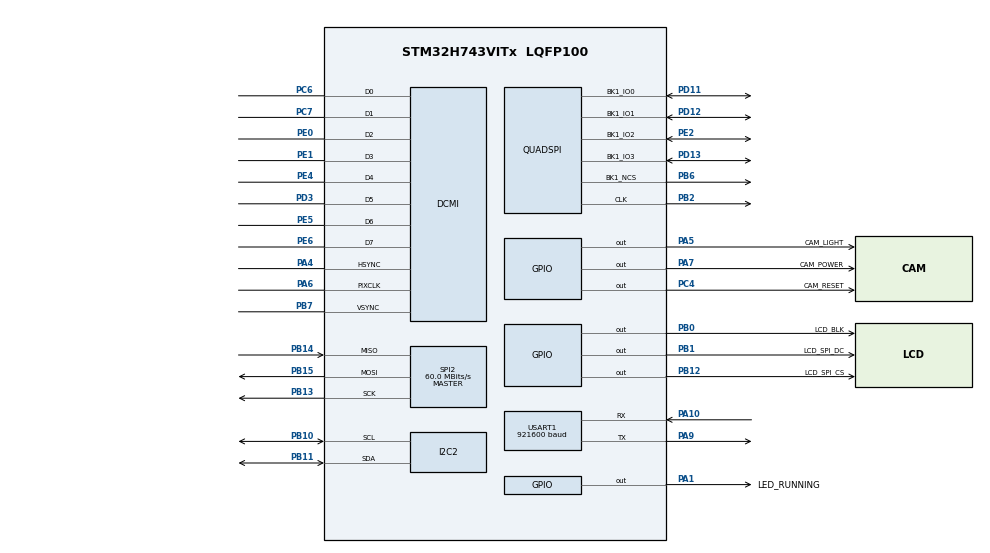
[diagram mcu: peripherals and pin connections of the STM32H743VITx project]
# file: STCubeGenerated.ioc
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CORTEX_M7.AccessPermission-Cortex_Memory_Protection_Unit_Region0_Settings=MPU_REGION_FULL_ACCESS
CORTEX_M7.AccessPermission-Cortex_Memory_Protection_Unit_Region1_Settings=MPU_REGION_FULL_ACCESS
CORTEX_M7.AccessPermission-Cortex_Memory_Protection_Unit_Region2_Settings=MPU_REGION_FULL_ACCESS
CORTEX_M7.AccessPermission-Cortex_Memory_Protection_Unit_Region3_Settings=MPU_REGION_FULL_ACCESS
CORTEX_M7.BaseAddress-Cortex_Memory_Protection_Unit_Region0_Settings=0x24000000
CORTEX_M7.BaseAddress-Cortex_Memory_Protection_Unit_Region1_Settings=0x30000000
CORTEX_M7.BaseAddress-Cortex_Memory_Protection_Unit_Region2_Settings=0x30040000
CORTEX_M7.BaseAddress-Cortex_Memory_Protection_Unit_Region3_Settings=0x38000000
CORTEX_M7.CPU_DCache=Enabled
CORTEX_M7.CPU_ICache=Enabled
CORTEX_M7.Enable-Cortex_Memory_Protection_Unit_Region0_Settings=MPU_REGION_ENABLE
CORTEX_M7.Enable-Cortex_Memory_Protection_Unit_Region1_Settings=MPU_REGION_ENABLE
CORTEX_M7.Enable-Cortex_Memory_Protection_Unit_Region2_Settings=MPU_REGION_ENABLE
CORTEX_M7.Enable-Cortex_Memory_Protection_Unit_Region3_Settings=MPU_REGION_ENABLE
CORTEX_M7.IsBufferable-Cortex_Memory_Protection_Unit_Region0_Settings=MPU_ACCESS_BUFFERABLE
CORTEX_M7.IsBufferable-Cortex_Memory_Protection_Unit_Region1_Settings=MPU_ACCESS_BUFFERABLE
CORTEX_M7.IsBufferable-Cortex_Memory_Protection_Unit_Region2_Settings=MPU_ACCESS_BUFFERABLE
CORTEX_M7.IsBufferable-Cortex_Memory_Protection_Unit_Region3_Settings=MPU_ACCESS_BUFFERABLE
CORTEX_M7.IsCacheable-Cortex_Memory_Protection_Unit_Region0_Settings=MPU_ACCESS_CACHEABLE
CORTEX_M7.IsCacheable-Cortex_Memory_Protection_Unit_Region1_Settings=MPU_ACCESS_CACHEABLE
CORTEX_M7.IsCacheable-Cortex_Memory_Protection_Unit_Region2_Settings=MPU_ACCESS_CACHEABLE
CORTEX_M7.IsCacheable-Cortex_Memory_Protection_Unit_Region3_Settings=MPU_ACCESS_CACHEABLE
CORTEX_M7.IsShareable-Cortex_Memory_Protection_Unit_Region0_Settings=MPU_ACCESS_NOT_SHAREABLE
CORTEX_M7.IsShareable-Cortex_Memory_Protection_Unit_Region1_Settings=MPU_ACCESS_NOT_SHAREABLE
CORTEX_M7.IsShareable-Cortex_Memory_Protection_Unit_Region2_Settings=MPU_ACCESS_NOT_SHAREABLE
CORTEX_M7.IsShareable-Cortex_Memory_Protection_Unit_Region3_Settings=MPU_ACCESS_NOT_SHAREABLE
CORTEX_M7.MPU_Control=MPU_PRIVILEGED_DEFAULT
CORTEX_M7.Size-Cortex_Memory_Protection_Unit_Region0_Settings=MPU_REGION_SIZE_512KB
CORTEX_M7.Size-Cortex_Memory_Protection_Unit_Region1_Settings=MPU_REGION_SIZE_256KB
CORTEX_M7.Size-Cortex_Memory_Protection_Unit_Region2_Settings=MPU_REGION_SIZE_32KB
CORTEX_M7.Size-Cortex_Memory_Protection_Unit_Region3_Settings=MPU_REGION_SIZE_64KB
CORTEX_M7.TypeExtField-Cortex_Memory_Protection_Unit_Region0_Settings=MPU_TEX_LEVEL1
CORTEX_M7.TypeExtField-Cortex_Memory_Protection_Unit_Region1_Settings=MPU_TEX_LEVEL1
CORTEX_M7.TypeExtField-Cortex_Memory_Protection_Unit_Region2_Settings=MPU_TEX_LEVEL1
CORTEX_M7.TypeExtField-Cortex_Memory_Protection_Unit_Region3_Settings=MPU_TEX_LEVEL1
DCMI.PCKPolarity=DCMI_PCKPOLARITY_RISING
DCMI.VSPolarity=DCMI_VSPOLARITY_LOW
Dma.DCMI.2.Direction=DMA_PERIPH_TO_MEMORY
Dma.DCMI.2.EventEnable=DISABLE
Dma.DCMI.2.FIFOMode=DMA_FIFOMODE_ENABLE
Dma.DCMI.2.FIFOThreshold=DMA_FIFO_THRESHOLD_FULL
Dma.DCMI.2.Instance=DMA2_Stream0
Dma.DCMI.2.MemBurst=DMA_MBURST_SINGLE
Dma.DCMI.2.MemDataAlignment=DMA_MDATAALIGN_WORD
Dma.DCMI.2.MemInc=DMA_MINC_ENABLE
Dma.DCMI.2.Mode=DMA_NORMAL
Dma.DCMI.2.PeriphBurst=DMA_PBURST_SINGLE
Dma.DCMI.2.PeriphDataAlignment=DMA_PDATAALIGN_WORD
Dma.DCMI.2.PeriphInc=DMA_PINC_DISABLE
Dma.DCMI.2.Polarity=HAL_DMAMUX_REQ_GEN_RISING
Dma.DCMI.2.Priority=DMA_PRIORITY_VERY_HIGH
Dma.DCMI.2.RequestNumber=1
Dma.DCMI.2.SignalID=NONE
Dma.DCMI.2.SyncEnable=DISABLE
Dma.DCMI.2.SyncPolarity=HAL_DMAMUX_SYNC_NO_EVENT
Dma.DCMI.2.SyncRequestNumber=1
Dma.DCMI.2.SyncSignalID=NONE
Dma.Request0=USART1_RX
Dma.Request1=SPI2_TX
Dma.Request2=DCMI
Dma.Request3=USART1_TX
Dma.SPI2_TX.1.Direction=DMA_MEMORY_TO_PERIPH
Dma.SPI2_TX.1.EventEnable=DISABLE
Dma.SPI2_TX.1.FIFOMode=DMA_FIFOMODE_DISABLE
Dma.SPI2_TX.1.Instance=DMA1_Stream1
Dma.SPI2_TX.1.MemDataAlignment=DMA_MDATAALIGN_BYTE
Dma.SPI2_TX.1.MemInc=DMA_MINC_ENABLE
Dma.SPI2_TX.1.Mode=DMA_NORMAL
Dma.SPI2_TX.1.PeriphDataAlignment=DMA_PDATAALIGN_BYTE
Dma.SPI2_TX.1.PeriphInc=DMA_PINC_DISABLE
Dma.SPI2_TX.1.Polarity=HAL_DMAMUX_REQ_GEN_RISING
Dma.SPI2_TX.1.Priority=DMA_PRIORITY_MEDIUM
Dma.SPI2_TX.1.RequestNumber=1
Dma.SPI2_TX.1.SignalID=NONE
Dma.SPI2_TX.1.SyncEnable=DISABLE
Dma.SPI2_TX.1.SyncPolarity=HAL_DMAMUX_SYNC_NO_EVENT
Dma.SPI2_TX.1.SyncRequestNumber=1
Dma.SPI2_TX.1.SyncSignalID=NONE
Dma.USART1_RX.0.Direction=DMA_PERIPH_TO_MEMORY
Dma.USART1_RX.0.EventEnable=DISABLE
Dma.USART1_RX.0.FIFOMode=DMA_FIFOMODE_DISABLE
Dma.USART1_RX.0.Instance=DMA1_Stream0
Dma.USART1_RX.0.MemDataAlignment=DMA_MDATAALIGN_BYTE
Dma.USART1_RX.0.MemInc=DMA_MINC_ENABLE
Dma.USART1_RX.0.Mode=DMA_NORMAL
Dma.USART1_RX.0.PeriphDataAlignment=DMA_PDATAALIGN_BYTE
Dma.USART1_RX.0.PeriphInc=DMA_PINC_DISABLE
Dma.USART1_RX.0.Polarity=HAL_DMAMUX_REQ_GEN_RISING
Dma.USART1_RX.0.Priority=DMA_PRIORITY_LOW
Dma.USART1_RX.0.RequestNumber=1
Dma.USART1_RX.0.SignalID=NONE
Dma.USART1_RX.0.SyncEnable=DISABLE
Dma.USART1_RX.0.SyncPolarity=HAL_DMAMUX_SYNC_NO_EVENT
Dma.USART1_RX.0.SyncRequestNumber=1
Dma.USART1_RX.0.SyncSignalID=NONE
Dma.USART1_TX.3.Direction=DMA_MEMORY_TO_PERIPH
Dma.USART1_TX.3.EventEnable=DISABLE
Dma.USART1_TX.3.FIFOMode=DMA_FIFOMODE_DISABLE
Dma.USART1_TX.3.Instance=DMA1_Stream2
Dma.USART1_TX.3.MemDataAlignment=DMA_MDATAALIGN_BYTE
Dma.USART1_TX.3.MemInc=DMA_MINC_ENABLE
Dma.USART1_TX.3.Mode=DMA_NORMAL
Dma.USART1_TX.3.PeriphDataAlignment=DMA_PDATAALIGN_BYTE
Dma.USART1_TX.3.PeriphInc=DMA_PINC_DISABLE
Dma.USART1_TX.3.Polarity=HAL_DMAMUX_REQ_GEN_RISING
Dma.USART1_TX.3.Priority=DMA_PRIORITY_LOW
Dma.USART1_TX.3.RequestNumber=1
Dma.USART1_TX.3.SignalID=NONE
Dma.USART1_TX.3.SyncEnable=DISABLE
Dma.USART1_TX.3.SyncPolarity=HAL_DMAMUX_SYNC_NO_EVENT
Dma.USART1_TX.3.SyncRequestNumber=1
Dma.USART1_TX.3.SyncSignalID=NONE
I2C2.Timing=0x307075B1
JPEG.JPEG_RGB_FORMAT=JPEG_RGB565
JPEG.USE_JPEG_DECODER=0
Mcu.Family=STM32H7
Mcu.Name=STM32H743VITx
Mcu.Package=LQFP100
Mdma.MDMA_Channel0.JPEG_INFIFO_TH.0.BlockCount=0
Mdma.MDMA_Channel0.JPEG_INFIFO_TH.0.BlockDataLength=0
Mdma.MDMA_Channel0.JPEG_INFIFO_TH.0.BufferTransferLength=32
Mdma.MDMA_Channel0.JPEG_INFIFO_TH.0.CircularMode=MDMA_LINEAR_LIST
Mdma.MDMA_Channel0.JPEG_INFIFO_TH.0.DataAlignment=MDMA_DATAALIGN_PACKENABLE
Mdma.MDMA_Channel0.JPEG_INFIFO_TH.0.DestBlockAddressOffset=0
Mdma.MDMA_Channel0.JPEG_INFIFO_TH.0.DestBurst=MDMA_DEST_BURST_8BEATS
Mdma.MDMA_Channel0.JPEG_INFIFO_TH.0.DestDataSize=MDMA_DEST_DATASIZE_WORD
Mdma.MDMA_Channel0.JPEG_INFIFO_TH.0.DestinationInc=MDMA_DEST_INC_DISABLE
Mdma.MDMA_Channel0.JPEG_INFIFO_TH.0.DstAddress=0
Mdma.MDMA_Channel0.JPEG_INFIFO_TH.0.Endianness=MDMA_LITTLE_ENDIANNESS_PRESERVE
Mdma.MDMA_Channel0.JPEG_INFIFO_TH.0.Instance=MDMA_Channel0
Mdma.MDMA_Channel0.JPEG_INFIFO_TH.0.MaskAddress=0
Mdma.MDMA_Channel0.JPEG_INFIFO_TH.0.MaskData=0
Mdma.MDMA_Channel0.JPEG_INFIFO_TH.0.Priority=MDMA_PRIORITY_LOW
Mdma.MDMA_Channel0.JPEG_INFIFO_TH.0.Rank=First
Mdma.MDMA_Channel0.JPEG_INFIFO_TH.0.SourceBlockAddressOffset=0
Mdma.MDMA_Channel0.JPEG_INFIFO_TH.0.SourceBurst=MDMA_SOURCE_BURST_4BEATS
Mdma.MDMA_Channel0.JPEG_INFIFO_TH.0.SourceDataSize=MDMA_SRC_DATASIZE_DOUBLEWORD
Mdma.MDMA_Channel0.JPEG_INFIFO_TH.0.SourceInc=MDMA_SRC_INC_DOUBLEWORD
Mdma.MDMA_Channel0.JPEG_INFIFO_TH.0.SrcAddress=0
Mdma.MDMA_Channel0.JPEG_INFIFO_TH.0.TransferTriggerMode=MDMA_BUFFER_TRANSFER
Mdma.MDMA_Channel0.Request0=JPEG_INFIFO_TH
Mdma.MDMA_Channel0.RequestsNb=1
Mdma.MDMA_Channel1.JPEG_OUTFIFO_TH.0.BlockCount=0
Mdma.MDMA_Channel1.JPEG_OUTFIFO_TH.0.BlockDataLength=0
Mdma.MDMA_Channel1.JPEG_OUTFIFO_TH.0.BufferTransferLength=32
Mdma.MDMA_Channel1.JPEG_OUTFIFO_TH.0.CircularMode=MDMA_LINEAR_LIST
Mdma.MDMA_Channel1.JPEG_OUTFIFO_TH.0.DataAlignment=MDMA_DATAALIGN_PACKENABLE
Mdma.MDMA_Channel1.JPEG_OUTFIFO_TH.0.DestBlockAddressOffset=0
Mdma.MDMA_Channel1.JPEG_OUTFIFO_TH.0.DestBurst=MDMA_DEST_BURST_4BEATS
Mdma.MDMA_Channel1.JPEG_OUTFIFO_TH.0.DestDataSize=MDMA_DEST_DATASIZE_DOUBLEWORD
Mdma.MDMA_Channel1.JPEG_OUTFIFO_TH.0.DestinationInc=MDMA_DEST_INC_DOUBLEWORD
Mdma.MDMA_Channel1.JPEG_OUTFIFO_TH.0.DstAddress=0
Mdma.MDMA_Channel1.JPEG_OUTFIFO_TH.0.Endianness=MDMA_LITTLE_ENDIANNESS_PRESERVE
Mdma.MDMA_Channel1.JPEG_OUTFIFO_TH.0.Instance=MDMA_Channel1
Mdma.MDMA_Channel1.JPEG_OUTFIFO_TH.0.MaskAddress=0
Mdma.MDMA_Channel1.JPEG_OUTFIFO_TH.0.MaskData=0
Mdma.MDMA_Channel1.JPEG_OUTFIFO_TH.0.Priority=MDMA_PRIORITY_LOW
Mdma.MDMA_Channel1.JPEG_OUTFIFO_TH.0.Rank=First
Mdma.MDMA_Channel1.JPEG_OUTFIFO_TH.0.SourceBlockAddressOffset=0
Mdma.MDMA_Channel1.JPEG_OUTFIFO_TH.0.SourceBurst=MDMA_SOURCE_BURST_8BEATS
Mdma.MDMA_Channel1.JPEG_OUTFIFO_TH.0.SourceDataSize=MDMA_SRC_DATASIZE_WORD
Mdma.MDMA_Channel1.JPEG_OUTFIFO_TH.0.SourceInc=MDMA_SRC_INC_DISABLE
Mdma.MDMA_Channel1.JPEG_OUTFIFO_TH.0.SrcAddress=0
Mdma.MDMA_Channel1.JPEG_OUTFIFO_TH.0.TransferTriggerMode=MDMA_BUFFER_TRANSFER
Mdma.MDMA_Channel1.Request0=JPEG_OUTFIFO_TH
Mdma.MDMA_Channel1.RequestsNb=1
Mdma.RequestSet0=MDMA_Channel0
Mdma.RequestSet1=MDMA_Channel1
Mdma.RequestSetsNb=2
NVIC.DCMI_IRQn=true\:6\:0\:true\:false\:true\:true\:true
NVIC.DMA1_Stream0_IRQn=true\:13\:0\:true\:false\:true\:false\:true
NVIC.DMA1_Stream1_IRQn=true\:9\:0\:true\:false\:true\:false\:true
NVIC.DMA1_Stream2_IRQn=true\:13\:0\:true\:false\:true\:false\:true
NVIC.DMA2_Stream0_IRQn=true\:7\:0\:true\:false\:true\:false\:true
NVIC.JPEG_IRQn=true\:4\:0\:true\:false\:true\:true\:true
NVIC.MDMA_IRQn=true\:3\:0\:true\:false\:true\:false\:true
NVIC.PriorityGroup=NVIC_PRIORITYGROUP_4
NVIC.QUADSPI_IRQn=true\:4\:0\:true\:false\:true\:true\:true
NVIC.SPI2_IRQn=true\:8\:0\:true\:false\:true\:true\:true
NVIC.USART1_IRQn=true\:12\:0\:true\:false\:true\:true\:true
PA1.GPIO_Label=LED_RUNNING
PA1.GPIO_PuPd=GPIO_PULLUP
PA1.PinState=GPIO_PIN_SET
PA1.Signal=GPIO_Output
PA10.GPIO_PuPd=GPIO_PULLUP
PA10.GPIO_Speed=GPIO_SPEED_FREQ_VERY_HIGH
PA10.Mode=Asynchronous
PA10.Signal=USART1_RX
PA4.GPIO_Speed=GPIO_SPEED_FREQ_VERY_HIGH
PA4.Mode=Slave_8_bits_External_Synchro
PA4.Signal=DCMI_HSYNC
PA5.GPIO_Label=CAM_LIGHT
PA5.GPIO_PuPd=GPIO_PULLDOWN
PA5.Signal=GPIO_Output
PA6.GPIO_Speed=GPIO_SPEED_FREQ_VERY_HIGH
PA6.Mode=Slave_8_bits_External_Synchro
PA6.Signal=DCMI_PIXCLK
PA7.GPIO_Label=CAM_POWER
PA7.GPIO_PuPd=GPIO_PULLUP
PA7.PinState=GPIO_PIN_SET
PA7.Signal=GPIO_Output
PA9.GPIO_PuPd=GPIO_PULLUP
PA9.GPIO_Speed=GPIO_SPEED_FREQ_VERY_HIGH
PA9.Mode=Asynchronous
PA9.Signal=USART1_TX
PB0.GPIO_Label=LCD_BLK
PB0.GPIO_PuPd=GPIO_PULLUP
PB0.GPIO_Speed=GPIO_SPEED_FREQ_LOW
PB0.PinState=GPIO_PIN_SET
PB0.Signal=GPIO_Output
PB1.GPIO_Label=LCD_SPI_DC
PB1.GPIO_PuPd=GPIO_PULLUP
PB1.GPIO_Speed=GPIO_SPEED_FREQ_VERY_HIGH
PB1.PinState=GPIO_PIN_SET
PB1.Signal=GPIO_Output
PB10.GPIO_Pu=GPIO_PULLUP
PB10.GPIO_Speed=GPIO_SPEED_FREQ_VERY_HIGH
PB10.Mode=I2C
PB10.Signal=I2C2_SCL
PB11.GPIO_Pu=GPIO_PULLUP
PB11.GPIO_Speed=GPIO_SPEED_FREQ_VERY_HIGH
PB11.Mode=I2C
PB11.Signal=I2C2_SDA
PB12.GPIO_Label=LCD_SPI_CS
PB12.GPIO_PuPd=GPIO_PULLUP
PB12.GPIO_Speed=GPIO_SPEED_FREQ_VERY_HIGH
PB12.PinState=GPIO_PIN_SET
PB12.Signal=GPIO_Output
PB13.GPIO_Speed=GPIO_SPEED_FREQ_VERY_HIGH
PB13.Mode=Full_Duplex_Master
PB13.Signal=SPI2_SCK
PB14.GPIO_Speed=GPIO_SPEED_FREQ_VERY_HIGH
PB14.Mode=Full_Duplex_Master
PB14.Signal=SPI2_MISO
PB15.GPIO_Speed=GPIO_SPEED_FREQ_VERY_HIGH
PB15.Mode=Full_Duplex_Master
PB15.Signal=SPI2_MOSI
PB2.GPIO_PuPd=GPIO_NOPULL
PB2.GPIO_Speed=GPIO_SPEED_FREQ_VERY_HIGH
PB2.Mode=Single Bank 1
PB2.Signal=QUADSPI_CLK
PB6.GPIO_FM6=__NULL
PB6.GPIO_PuPd=GPIO_PULLUP
PB6.GPIO_Speed=GPIO_SPEED_FREQ_VERY_HIGH
PB6.Mode=Single Bank 1
PB6.Signal=QUADSPI_BK1_NCS
PB7.GPIO_FM7=__NULL
PB7.GPIO_Speed=GPIO_SPEED_FREQ_VERY_HIGH
PB7.Mode=Slave_8_bits_External_Synchro
PB7.Signal=DCMI_VSYNC
PC4.GPIO_Label=CAM_RESET
PC4.GPIO_PuPd=GPIO_PULLUP
PC4.PinState=GPIO_PIN_SET
PC4.Signal=GPIO_Output
PC6.GPIO_Speed=GPIO_SPEED_FREQ_VERY_HIGH
PC6.Mode=Slave_8_bits_External_Synchro
PC6.Signal=DCMI_D0
PC7.GPIO_Speed=GPIO_SPEED_FREQ_VERY_HIGH
PC7.Mode=Slave_8_bits_External_Synchro
PC7.Signal=DCMI_D1
PD11.GPIO_Speed=GPIO_SPEED_FREQ_VERY_HIGH
PD11.Mode=Single Bank 1
PD11.Signal=QUADSPI_BK1_IO0
PD12.GPIO_PuPd=GPIO_NOPULL
PD12.GPIO_Speed=GPIO_SPEED_FREQ_VERY_HIGH
PD12.Mode=Single Bank 1
PD12.Signal=QUADSPI_BK1_IO1
PD13.GPIO_Speed=GPIO_SPEED_FREQ_VERY_HIGH
PD13.Mode=Single Bank 1
PD13.Signal=QUADSPI_BK1_IO3
PD3.GPIO_Speed=GPIO_SPEED_FREQ_VERY_HIGH
PD3.Mode=Slave_8_bits_External_Synchro
PD3.Signal=DCMI_D5
PE0.GPIO_Speed=GPIO_SPEED_FREQ_VERY_HIGH
PE0.Mode=Slave_8_bits_External_Synchro
PE0.Signal=DCMI_D2
PE1.GPIO_Speed=GPIO_SPEED_FREQ_VERY_HIGH
PE1.Mode=Slave_8_bits_External_Synchro
PE1.Signal=DCMI_D3
PE2.GPIO_Speed=GPIO_SPEED_FREQ_VERY_HIGH
PE2.Mode=Single Bank 1
PE2.Signal=QUADSPI_BK1_IO2
PE4.GPIO_Speed=GPIO_SPEED_FREQ_VERY_HIGH
PE4.Mode=Slave_8_bits_External_Synchro
PE4.Signal=DCMI_D4
PE5.GPIO_Speed=GPIO_SPEED_FREQ_VERY_HIGH
PE5.Mode=Slave_8_bits_External_Synchro
PE5.Signal=DCMI_D6
PE6.GPIO_Speed=GPIO_SPEED_FREQ_VERY_HIGH
PE6.Mode=Slave_8_bits_External_Synchro
PE6.Signal=DCMI_D7
PH0-OSC_IN\ (PH0).Mode=HSE-External-Oscillator
PH0-OSC_IN\ (PH0).Signal=RCC_OSC_IN
PH1-OSC_OUT\ (PH1).Mode=HSE-External-Oscillator
PH1-OSC_OUT\ (PH1).Signal=RCC_OSC_OUT
ProjectManager.HeapSize=0x000
ProjectManager.StackSize=0x4000
ProjectManager.TargetToolchain=Other Toolchains (GPDSC)
QUADSPI.ChipSelectHighTime=QSPI_CS_HIGH_TIME_2_CYCLE
QUADSPI.ClockPrescaler=1
QUADSPI.FifoThreshold=32
QUADSPI.FlashSize=2
QUADSPI.SampleShifting=QSPI_SAMPLE_SHIFTING_HALFCYCLE
RCC.ADCFreq_Value=180000000
RCC.APB1Freq_Value=120000000
RCC.APB2Freq_Value=120000000
RCC.APB3Freq_Value=120000000
RCC.APB4Freq_Value=120000000
RCC.CortexFreq_Value=480000000
RCC.D1PPRE=RCC_APB3_DIV2
RCC.D2PPRE1=RCC_APB1_DIV2
RCC.D2PPRE2=RCC_APB2_DIV2
RCC.D3PPRE=RCC_APB4_DIV2
RCC.DIVM1=5
RCC.DIVM2=5
RCC.DIVN1=192
RCC.DIVN2=180
RCC.DIVP2=5
RCC.DIVQ1=8
RCC.DIVQ2=4
RCC.HCLKFreq_Value=240000000
RCC.HPRE=RCC_HCLK_DIV2
RCC.PLLSourceVirtual=RCC_PLLSOURCE_HSE
RCC.ProductRev=revV
RCC.SYSCLKFreq_VALUE=480000000
RCC.SYSCLKSource=RCC_SYSCLKSOURCE_PLLCLK
RCC.USBFreq_Value=120000000
SPI2.BaudRatePrescaler=SPI_BAUDRATEPRESCALER_2
SPI2.CLKPhase=SPI_PHASE_2EDGE
SPI2.CLKPolarity=SPI_POLARITY_HIGH
SPI2.CalculateBaudRate=60.0 MBits/s
SPI2.DataSize=SPI_DATASIZE_8BIT
SPI2.Direction=SPI_DIRECTION_2LINES
SPI2.Mode=SPI_MODE_MASTER
SPI2.VirtualType=VM_MASTER
USART1.BaudRate=921600
USART1.VirtualMode-Asynchronous=VM_ASYNC
VP_JPEG_VS_JPEG.Mode=JPEG_Activate
board=custom

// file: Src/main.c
/* USER CODE BEGIN Header */
/**
  ******************************************************************************
  * @file           : main.c
  * @brief          : Main program body
  ******************************************************************************
  * @attention
  *
  * <h2><center>&copy; Copyright (c) 2021 STMicroelectronics.
  * All rights reserved.</center></h2>
  *
  * This software component is licensed by ST under BSD 3-Clause license,
  * the "License"; You may not use this file except in compliance with the
  * License. You may obtain a copy of the License at:
  *                        opensource.org/licenses/BSD-3-Clause
  *
  ******************************************************************************
  */
/* USER CODE END Header */
#include "main.h"
#include "dcmi.h"
#include "dma.h"
#include "i2c.h"
#include "jpeg.h"
#include "mdma.h"
#include "quadspi.h"
#include "spi.h"
#include "usart.h"
#include "gpio.h"

/* USER CODE BEGIN Includes */
#include "RTE_Components.h"
#include CMSIS_device_header
#include "cmsis_os2.h"
extern osThreadId_t system_thread_id;
extern __NO_RETURN void system_thread(void *argument);
/* USER CODE END Includes */

void SystemClock_Config(void);
static void MPU_Config(void);

int main(void)
{

  /* MPU Configuration--------------------------------------------------------*/
  MPU_Config();

  /* Enable I-Cache---------------------------------------------------------*/
  SCB_EnableICache();

  /* Enable D-Cache---------------------------------------------------------*/
  SCB_EnableDCache();

  /* MCU Configuration--------------------------------------------------------*/

  /* Reset of all peripherals, Initializes the Flash interface and the Systick. */
  HAL_Init();

  /* Configure the system clock */
  SystemClock_Config();

  /* Initialize all configured peripherals */
  MX_GPIO_Init();
  MX_DMA_Init();
  MX_USART1_UART_Init();
  MX_SPI2_Init();
  MX_I2C2_Init();
  MX_QUADSPI_Init();
  MX_DCMI_Init();
  MX_MDMA_Init();
  MX_JPEG_Init();
  /* USER CODE BEGIN 2 */
  osKernelInitialize();                 // Initialize CMSIS-RTOS
  system_thread_id = osThreadNew(system_thread, NULL, NULL);    // Create application main thread
  osThreadSetPriority(system_thread_id, osPriorityRealtime);
  osKernelStart();                      // Start thread execution
  /* USER CODE END 2 */

  /* Infinite loop */
  while (1)
  {

  }
}

void SystemClock_Config(void)
{
  RCC_OscInitTypeDef RCC_OscInitStruct = {0};
  RCC_ClkInitTypeDef RCC_ClkInitStruct = {0};

  /** Supply configuration update enable
  */
  HAL_PWREx_ConfigSupply(PWR_LDO_SUPPLY);
  /** Configure the main internal regulator output voltage
  */
  __HAL_PWR_VOLTAGESCALING_CONFIG(PWR_REGULATOR_VOLTAGE_SCALE0);

  while(!__HAL_PWR_GET_FLAG(PWR_FLAG_VOSRDY)) {}
  /** Initializes the RCC Oscillators according to the specified parameters
  * in the RCC_OscInitTypeDef structure.
  */
  RCC_OscInitStruct.OscillatorType = RCC_OSCILLATORTYPE_HSE;
  RCC_OscInitStruct.HSEState = RCC_HSE_ON;
  RCC_OscInitStruct.PLL.PLLState = RCC_PLL_ON;
  RCC_OscInitStruct.PLL.PLLSource = RCC_PLLSOURCE_HSE;
  RCC_OscInitStruct.PLL.PLLM = 5;
  RCC_OscInitStruct.PLL.PLLN = 192;
  RCC_OscInitStruct.PLL.PLLP = 2;
  RCC_OscInitStruct.PLL.PLLQ = 8;
  RCC_OscInitStruct.PLL.PLLR = 2;
  RCC_OscInitStruct.PLL.PLLRGE = RCC_PLL1VCIRANGE_2;
  RCC_OscInitStruct.PLL.PLLVCOSEL = RCC_PLL1VCOWIDE;
  RCC_OscInitStruct.PLL.PLLFRACN = 0;
  if (HAL_RCC_OscConfig(&RCC_OscInitStruct) != HAL_OK)
  {
    Error_Handler();
  }
  /** Initializes the CPU, AHB and APB buses clocks
  */
  RCC_ClkInitStruct.ClockType = RCC_CLOCKTYPE_HCLK|RCC_CLOCKTYPE_SYSCLK
                              |RCC_CLOCKTYPE_PCLK1|RCC_CLOCKTYPE_PCLK2
                              |RCC_CLOCKTYPE_D3PCLK1|RCC_CLOCKTYPE_D1PCLK1;
  RCC_ClkInitStruct.SYSCLKSource = RCC_SYSCLKSOURCE_PLLCLK;
  RCC_ClkInitStruct.SYSCLKDivider = RCC_SYSCLK_DIV1;
  RCC_ClkInitStruct.AHBCLKDivider = RCC_HCLK_DIV2;
  RCC_ClkInitStruct.APB3CLKDivider = RCC_APB3_DIV2;
  RCC_ClkInitStruct.APB1CLKDivider = RCC_APB1_DIV2;
  RCC_ClkInitStruct.APB2CLKDivider = RCC_APB2_DIV2;
  RCC_ClkInitStruct.APB4CLKDivider = RCC_APB4_DIV2;

  if (HAL_RCC_ClockConfig(&RCC_ClkInitStruct, FLASH_LATENCY_4) != HAL_OK)
  {
    Error_Handler();
  }
}

/* MPU Configuration */

void MPU_Config(void)
{
  MPU_Region_InitTypeDef MPU_InitStruct = {0};

  /* Disables the MPU */
  HAL_MPU_Disable();
  /** Initializes and configures the Region and the memory to be protected
  */
  MPU_InitStruct.Enable = MPU_REGION_ENABLE;
  MPU_InitStruct.Number = MPU_REGION_NUMBER0;
  MPU_InitStruct.BaseAddress = 0x24000000;
  MPU_InitStruct.Size = MPU_REGION_SIZE_512KB;
  MPU_InitStruct.SubRegionDisable = 0x0;
  MPU_InitStruct.TypeExtField = MPU_TEX_LEVEL1;
  MPU_InitStruct.AccessPermission = MPU_REGION_FULL_ACCESS;
  MPU_InitStruct.DisableExec = MPU_INSTRUCTION_ACCESS_ENABLE;
  MPU_InitStruct.IsShareable = MPU_ACCESS_NOT_SHAREABLE;
  MPU_InitStruct.IsCacheable = MPU_ACCESS_CACHEABLE;
  MPU_InitStruct.IsBufferable = MPU_ACCESS_BUFFERABLE;

  HAL_MPU_ConfigRegion(&MPU_InitStruct);
  /** Initializes and configures the Region and the memory to be protected
  */
  MPU_InitStruct.Number = MPU_REGION_NUMBER1;
  MPU_InitStruct.BaseAddress = 0x30000000;
  MPU_InitStruct.Size = MPU_REGION_SIZE_256KB;

  HAL_MPU_ConfigRegion(&MPU_InitStruct);
  /** Initializes and configures the Region and the memory to be protected
  */
  MPU_InitStruct.Number = MPU_REGION_NUMBER2;
  MPU_InitStruct.BaseAddress = 0x30040000;
  MPU_InitStruct.Size = MPU_REGION_SIZE_32KB;

  HAL_MPU_ConfigRegion(&MPU_InitStruct);
  /** Initializes and configures the Region and the memory to be protected
  */
  MPU_InitStruct.Number = MPU_REGION_NUMBER3;
  MPU_InitStruct.BaseAddress = 0x38000000;
  MPU_InitStruct.Size = MPU_REGION_SIZE_64KB;

  HAL_MPU_ConfigRegion(&MPU_InitStruct);
  /* Enables the MPU */
  HAL_MPU_Enable(MPU_PRIVILEGED_DEFAULT);

}

void Error_Handler(void)
{
  __disable_irq();
  while (1)
  {
  }
}

/************************ (C) COPYRIGHT STMicroelectronics *****END OF FILE****/
